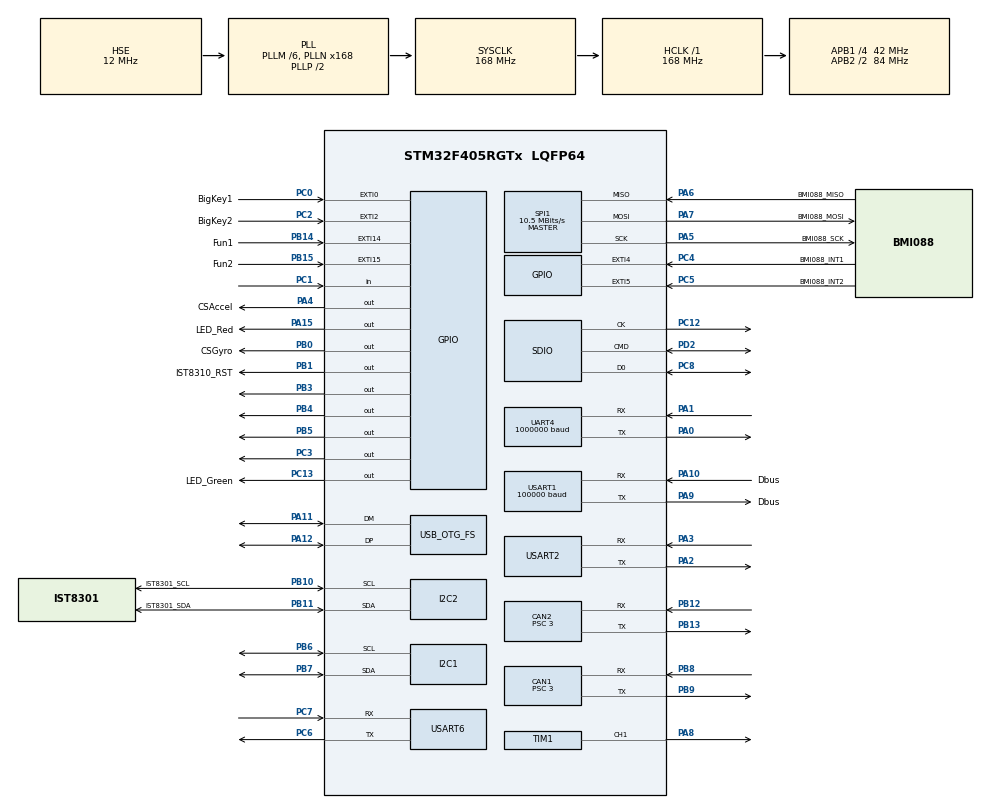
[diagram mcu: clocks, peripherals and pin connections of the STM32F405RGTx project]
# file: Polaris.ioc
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ADC1.Channel-0\#ChannelRegularConversion=ADC_CHANNEL_TEMPSENSOR
ADC1.Channel-1\#ChannelRegularConversion=ADC_CHANNEL_VREFINT
ADC1.Channel-2\#ChannelRegularConversion=ADC_CHANNEL_VBAT
ADC1.ContinuousConvMode=ENABLE
ADC1.DMAContinuousRequests=ENABLE
ADC1.EOCSelection=ADC_EOC_SEQ_CONV
ADC1.NbrOfConversion=3
ADC1.NbrOfConversionFlag=1
ADC1.Rank-0\#ChannelRegularConversion=1
ADC1.Rank-1\#ChannelRegularConversion=2
ADC1.Rank-2\#ChannelRegularConversion=3
ADC1.SamplingTime-0\#ChannelRegularConversion=ADC_SAMPLETIME_15CYCLES
ADC1.SamplingTime-1\#ChannelRegularConversion=ADC_SAMPLETIME_15CYCLES
ADC1.SamplingTime-2\#ChannelRegularConversion=ADC_SAMPLETIME_15CYCLES
ADC1.master=1
CAN1.BS1=CAN_BS1_9TQ
CAN1.BS2=CAN_BS2_4TQ
CAN1.CalculateBaudRate=1000000
CAN1.CalculateTimeBit=1000
CAN1.CalculateTimeQuantum=71.42857142857143
CAN1.Prescaler=3
CAN2.BS1=CAN_BS1_9TQ
CAN2.BS2=CAN_BS2_4TQ
CAN2.CalculateBaudRate=1000000
CAN2.CalculateTimeBit=1000
CAN2.CalculateTimeQuantum=71.42857142857143
CAN2.Prescaler=3
Dma.ADC1.7.Direction=DMA_PERIPH_TO_MEMORY
Dma.ADC1.7.FIFOMode=DMA_FIFOMODE_ENABLE
Dma.ADC1.7.FIFOThreshold=DMA_FIFO_THRESHOLD_FULL
Dma.ADC1.7.Instance=DMA2_Stream4
Dma.ADC1.7.MemBurst=DMA_MBURST_SINGLE
Dma.ADC1.7.MemDataAlignment=DMA_MDATAALIGN_WORD
Dma.ADC1.7.MemInc=DMA_MINC_ENABLE
Dma.ADC1.7.Mode=DMA_CIRCULAR
Dma.ADC1.7.PeriphBurst=DMA_PBURST_SINGLE
Dma.ADC1.7.PeriphDataAlignment=DMA_PDATAALIGN_WORD
Dma.ADC1.7.PeriphInc=DMA_PINC_DISABLE
Dma.ADC1.7.Priority=DMA_PRIORITY_LOW
Dma.I2C1_RX.6.Direction=DMA_PERIPH_TO_MEMORY
Dma.I2C1_RX.6.FIFOMode=DMA_FIFOMODE_DISABLE
Dma.I2C1_RX.6.Instance=DMA1_Stream0
Dma.I2C1_RX.6.MemDataAlignment=DMA_MDATAALIGN_BYTE
Dma.I2C1_RX.6.MemInc=DMA_MINC_ENABLE
Dma.I2C1_RX.6.Mode=DMA_CIRCULAR
Dma.I2C1_RX.6.PeriphDataAlignment=DMA_PDATAALIGN_BYTE
Dma.I2C1_RX.6.PeriphInc=DMA_PINC_DISABLE
Dma.I2C1_RX.6.Priority=DMA_PRIORITY_LOW
Dma.I2C1_TX.10.Direction=DMA_MEMORY_TO_PERIPH
Dma.I2C1_TX.10.FIFOMode=DMA_FIFOMODE_DISABLE
Dma.I2C1_TX.10.Instance=DMA1_Stream7
Dma.I2C1_TX.10.MemDataAlignment=DMA_MDATAALIGN_BYTE
Dma.I2C1_TX.10.MemInc=DMA_MINC_ENABLE
Dma.I2C1_TX.10.Mode=DMA_CIRCULAR
Dma.I2C1_TX.10.PeriphDataAlignment=DMA_PDATAALIGN_BYTE
Dma.I2C1_TX.10.PeriphInc=DMA_PINC_DISABLE
Dma.I2C1_TX.10.Priority=DMA_PRIORITY_VERY_HIGH
Dma.Request0=USART6_RX
Dma.Request1=USART2_RX
Dma.Request10=I2C1_TX
Dma.Request11=USART2_TX
Dma.Request12=UART4_TX
Dma.Request2=USART1_RX
Dma.Request3=UART4_RX
Dma.Request4=SPI1_RX
Dma.Request5=SPI1_TX
Dma.Request6=I2C1_RX
Dma.Request7=ADC1
Dma.Request8=SDIO_RX
Dma.Request9=SDIO_TX
Dma.SDIO_RX.8.Direction=DMA_PERIPH_TO_MEMORY
Dma.SDIO_RX.8.FIFOMode=DMA_FIFOMODE_ENABLE
Dma.SDIO_RX.8.FIFOThreshold=DMA_FIFO_THRESHOLD_FULL
Dma.SDIO_RX.8.Instance=DMA2_Stream6
Dma.SDIO_RX.8.MemBurst=DMA_MBURST_INC4
Dma.SDIO_RX.8.MemDataAlignment=DMA_MDATAALIGN_WORD
Dma.SDIO_RX.8.MemInc=DMA_MINC_ENABLE
Dma.SDIO_RX.8.Mode=DMA_PFCTRL
Dma.SDIO_RX.8.PeriphBurst=DMA_PBURST_INC4
Dma.SDIO_RX.8.PeriphDataAlignment=DMA_PDATAALIGN_WORD
Dma.SDIO_RX.8.PeriphInc=DMA_PINC_DISABLE
Dma.SDIO_RX.8.Priority=DMA_PRIORITY_LOW
Dma.SDIO_TX.9.Direction=DMA_MEMORY_TO_PERIPH
Dma.SDIO_TX.9.FIFOMode=DMA_FIFOMODE_ENABLE
Dma.SDIO_TX.9.FIFOThreshold=DMA_FIFO_THRESHOLD_FULL
Dma.SDIO_TX.9.Instance=DMA2_Stream3
Dma.SDIO_TX.9.MemBurst=DMA_MBURST_INC4
Dma.SDIO_TX.9.MemDataAlignment=DMA_MDATAALIGN_WORD
Dma.SDIO_TX.9.MemInc=DMA_MINC_ENABLE
Dma.SDIO_TX.9.Mode=DMA_PFCTRL
Dma.SDIO_TX.9.PeriphBurst=DMA_PBURST_INC4
Dma.SDIO_TX.9.PeriphDataAlignment=DMA_PDATAALIGN_WORD
Dma.SDIO_TX.9.PeriphInc=DMA_PINC_DISABLE
Dma.SDIO_TX.9.Priority=DMA_PRIORITY_LOW
Dma.SPI1_RX.4.Direction=DMA_PERIPH_TO_MEMORY
Dma.SPI1_RX.4.FIFOMode=DMA_FIFOMODE_DISABLE
Dma.SPI1_RX.4.Instance=DMA2_Stream0
Dma.SPI1_RX.4.MemDataAlignment=DMA_MDATAALIGN_BYTE
Dma.SPI1_RX.4.MemInc=DMA_MINC_ENABLE
Dma.SPI1_RX.4.Mode=DMA_CIRCULAR
Dma.SPI1_RX.4.PeriphDataAlignment=DMA_PDATAALIGN_BYTE
Dma.SPI1_RX.4.PeriphInc=DMA_PINC_DISABLE
Dma.SPI1_RX.4.Priority=DMA_PRIORITY_LOW
Dma.SPI1_TX.5.Direction=DMA_MEMORY_TO_PERIPH
Dma.SPI1_TX.5.FIFOMode=DMA_FIFOMODE_DISABLE
Dma.SPI1_TX.5.Instance=DMA2_Stream5
Dma.SPI1_TX.5.MemDataAlignment=DMA_MDATAALIGN_BYTE
Dma.SPI1_TX.5.MemInc=DMA_MINC_ENABLE
Dma.SPI1_TX.5.Mode=DMA_CIRCULAR
Dma.SPI1_TX.5.PeriphDataAlignment=DMA_PDATAALIGN_BYTE
Dma.SPI1_TX.5.PeriphInc=DMA_PINC_DISABLE
Dma.SPI1_TX.5.Priority=DMA_PRIORITY_LOW
Dma.UART4_RX.3.Direction=DMA_PERIPH_TO_MEMORY
Dma.UART4_RX.3.FIFOMode=DMA_FIFOMODE_DISABLE
Dma.UART4_RX.3.Instance=DMA1_Stream2
Dma.UART4_RX.3.MemDataAlignment=DMA_MDATAALIGN_BYTE
Dma.UART4_RX.3.MemInc=DMA_MINC_ENABLE
Dma.UART4_RX.3.Mode=DMA_CIRCULAR
Dma.UART4_RX.3.PeriphDataAlignment=DMA_PDATAALIGN_BYTE
Dma.UART4_RX.3.PeriphInc=DMA_PINC_DISABLE
Dma.UART4_RX.3.Priority=DMA_PRIORITY_LOW
Dma.UART4_TX.12.Direction=DMA_MEMORY_TO_PERIPH
Dma.UART4_TX.12.FIFOMode=DMA_FIFOMODE_DISABLE
Dma.UART4_TX.12.Instance=DMA1_Stream4
Dma.UART4_TX.12.MemDataAlignment=DMA_MDATAALIGN_BYTE
Dma.UART4_TX.12.MemInc=DMA_MINC_ENABLE
Dma.UART4_TX.12.Mode=DMA_NORMAL
Dma.UART4_TX.12.PeriphDataAlignment=DMA_PDATAALIGN_BYTE
Dma.UART4_TX.12.PeriphInc=DMA_PINC_DISABLE
Dma.UART4_TX.12.Priority=DMA_PRIORITY_LOW
Dma.USART1_RX.2.Direction=DMA_PERIPH_TO_MEMORY
Dma.USART1_RX.2.FIFOMode=DMA_FIFOMODE_DISABLE
Dma.USART1_RX.2.Instance=DMA2_Stream2
Dma.USART1_RX.2.MemDataAlignment=DMA_MDATAALIGN_BYTE
Dma.USART1_RX.2.MemInc=DMA_MINC_ENABLE
Dma.USART1_RX.2.Mode=DMA_CIRCULAR
Dma.USART1_RX.2.PeriphDataAlignment=DMA_PDATAALIGN_BYTE
Dma.USART1_RX.2.PeriphInc=DMA_PINC_DISABLE
Dma.USART1_RX.2.Priority=DMA_PRIORITY_LOW
Dma.USART2_RX.1.Direction=DMA_PERIPH_TO_MEMORY
Dma.USART2_RX.1.FIFOMode=DMA_FIFOMODE_DISABLE
Dma.USART2_RX.1.Instance=DMA1_Stream5
Dma.USART2_RX.1.MemDataAlignment=DMA_MDATAALIGN_BYTE
Dma.USART2_RX.1.MemInc=DMA_MINC_ENABLE
Dma.USART2_RX.1.Mode=DMA_CIRCULAR
Dma.USART2_RX.1.PeriphDataAlignment=DMA_PDATAALIGN_BYTE
Dma.USART2_RX.1.PeriphInc=DMA_PINC_DISABLE
Dma.USART2_RX.1.Priority=DMA_PRIORITY_LOW
Dma.USART2_TX.11.Direction=DMA_MEMORY_TO_PERIPH
Dma.USART2_TX.11.FIFOMode=DMA_FIFOMODE_DISABLE
Dma.USART2_TX.11.Instance=DMA1_Stream6
Dma.USART2_TX.11.MemDataAlignment=DMA_MDATAALIGN_BYTE
Dma.USART2_TX.11.MemInc=DMA_MINC_ENABLE
Dma.USART2_TX.11.Mode=DMA_NORMAL
Dma.USART2_TX.11.PeriphDataAlignment=DMA_PDATAALIGN_BYTE
Dma.USART2_TX.11.PeriphInc=DMA_PINC_DISABLE
Dma.USART2_TX.11.Priority=DMA_PRIORITY_LOW
Dma.USART6_RX.0.Direction=DMA_PERIPH_TO_MEMORY
Dma.USART6_RX.0.FIFOMode=DMA_FIFOMODE_DISABLE
Dma.USART6_RX.0.Instance=DMA2_Stream1
Dma.USART6_RX.0.MemDataAlignment=DMA_MDATAALIGN_BYTE
Dma.USART6_RX.0.MemInc=DMA_MINC_ENABLE
Dma.USART6_RX.0.Mode=DMA_CIRCULAR
Dma.USART6_RX.0.PeriphDataAlignment=DMA_PDATAALIGN_BYTE
Dma.USART6_RX.0.PeriphInc=DMA_PINC_DISABLE
Dma.USART6_RX.0.Priority=DMA_PRIORITY_LOW
FATFS.BSP.number=1
FATFS._CODE_PAGE=437
FATFS._FS_MINIMIZE=0
FATFS._USE_FIND=0
FATFS._USE_LFN=2
FATFS0.BSP.STBoard=false
FATFS0.BSP.api=Unknown
FATFS0.BSP.instance=PC1
FATFS0.BSP.ip=GPIO
FATFS0.BSP.mode=Input
FATFS0.BSP.name=Detect_SDIO
FATFS0.BSP.solution=PC1
FREERTOS.BinarySemaphores01=Shell_RxCMD,Dynamic,NULL
FREERTOS.INCLUDE_eTaskGetState=1
FREERTOS.INCLUDE_pcTaskGetTaskName=1
FREERTOS.INCLUDE_uxTaskGetStackHighWaterMark=1
FREERTOS.INCLUDE_uxTaskGetStackHighWaterMark2=1
FREERTOS.INCLUDE_vTaskCleanUpResources=1
FREERTOS.INCLUDE_vTaskDelayUntil=1
FREERTOS.INCLUDE_xQueueGetMutexHolder=1
FREERTOS.INCLUDE_xSemaphoreGetMutexHolder=1
FREERTOS.INCLUDE_xTaskAbortDelay=1
FREERTOS.INCLUDE_xTaskGetCurrentTaskHandle=1
FREERTOS.INCLUDE_xTaskGetHandle=1
FREERTOS.INCLUDE_xTimerPendFunctionCall=1
FREERTOS.Queues01=Key_Queue,16,uint16_t,0,Dynamic,NULL,NULL;Key_TriggerQueue,16,uint16_t,0,Dynamic,NULL,NULL
FREERTOS.Tasks01=Init_TASK,3,256,Init_Task,As weak,NULL,Dynamic,NULL,NULL;Ins_TASK,3,256,Ins_Task,As weak,NULL,Dynamic,NULL,NULL;Client_TASK,3,256,Client_Task,As weak,NULL,Dynamic,NULL,NULL;WatchDog_TASK,3,256,WatchDog_Task,As weak,NULL,Dynamic,NULL,NULL;Remote_TASK,3,256,Remote_Task,As weak,NULL,Dynamic,NULL,NULL;Comm_TASK,3,256,Comm_Task,As weak,NULL,Dynamic,NULL,NULL;Shell_TASK,2,256,Shell_Task,As weak,NULL,Dynamic,NULL,NULL;Quadruped_TASK,3,256,Quadruped_Task,As weak,NULL,Dynamic,NULL,NULL;WheelLeg_TASK,3,256,WheelLeg_Task,As weak,NULL,Dynamic,NULL,NULL;Gimbal_TASK,3,256,Gimbal_Task,As weak,NULL,Dynamic,NULL,NULL
FREERTOS.Timers01=Beeper_Timer,BeeperTimerCallback,osTimerPeriodic,As weak,NULL,Dynamic,NULL
FREERTOS.configCHECK_FOR_STACK_OVERFLOW=1
FREERTOS.configENABLE_FPU=1
FREERTOS.configGENERATE_RUN_TIME_STATS=1
FREERTOS.configIDLE_SHOULD_YIELD=1
FREERTOS.configMINIMAL_STACK_SIZE=256
FREERTOS.configRECORD_STACK_HIGH_ADDRESS=1
FREERTOS.configTIMER_TASK_PRIORITY=3
FREERTOS.configTIMER_TASK_STACK_DEPTH=256
FREERTOS.configUSE_APPLICATION_TASK_TAG=1
FREERTOS.configUSE_COUNTING_SEMAPHORES=0
FREERTOS.configUSE_DAEMON_TASK_STARTUP_HOOK=1
FREERTOS.configUSE_IDLE_HOOK=1
FREERTOS.configUSE_MALLOC_FAILED_HOOK=1
FREERTOS.configUSE_RECURSIVE_MUTEXES=0
FREERTOS.configUSE_STATS_FORMATTING_FUNCTIONS=1
FREERTOS.configUSE_TICK_HOOK=1
FREERTOS.configUSE_TIMERS=1
FREERTOS.configUSE_TRACE_FACILITY=1
I2C1.I2C_Mode=I2C_Fast
I2C2.I2C_Mode=I2C_Fast
Mcu.Family=STM32F4
Mcu.Name=STM32F405RGTx
Mcu.Package=LQFP64
NVIC.CAN1_RX0_IRQn=true\:5\:0\:true\:false\:true\:true\:true\:true\:true
NVIC.CAN1_RX1_IRQn=true\:5\:0\:false\:false\:true\:true\:true\:true\:true
NVIC.CAN2_RX0_IRQn=true\:5\:0\:false\:false\:true\:true\:true\:true\:true
NVIC.CAN2_RX1_IRQn=true\:5\:0\:false\:false\:true\:true\:true\:true\:true
NVIC.DMA1_Stream0_IRQn=true\:5\:0\:false\:false\:true\:true\:false\:true\:true
NVIC.DMA1_Stream2_IRQn=true\:5\:0\:false\:false\:true\:true\:false\:true\:true
NVIC.DMA1_Stream4_IRQn=true\:5\:0\:false\:false\:true\:true\:false\:true\:true
NVIC.DMA1_Stream5_IRQn=true\:5\:0\:false\:false\:true\:true\:false\:true\:true
NVIC.DMA1_Stream6_IRQn=true\:5\:0\:false\:false\:true\:true\:false\:true\:true
NVIC.DMA1_Stream7_IRQn=true\:5\:0\:false\:false\:true\:false\:false\:true\:true
NVIC.DMA2_Stream0_IRQn=true\:5\:0\:false\:false\:true\:true\:false\:true\:true
NVIC.DMA2_Stream1_IRQn=true\:5\:0\:false\:false\:true\:true\:false\:true\:true
NVIC.DMA2_Stream2_IRQn=true\:5\:0\:false\:false\:true\:true\:false\:true\:true
NVIC.DMA2_Stream3_IRQn=true\:5\:0\:false\:false\:true\:true\:false\:true\:true
NVIC.DMA2_Stream4_IRQn=true\:5\:0\:false\:false\:true\:true\:false\:true\:true
NVIC.DMA2_Stream5_IRQn=true\:5\:0\:false\:false\:true\:true\:false\:true\:true
NVIC.DMA2_Stream6_IRQn=true\:5\:0\:false\:false\:true\:true\:false\:true\:true
NVIC.EXTI0_IRQn=true\:5\:0\:false\:false\:true\:true\:true\:true\:true
NVIC.EXTI15_10_IRQn=true\:5\:0\:false\:false\:true\:true\:true\:true\:true
NVIC.EXTI2_IRQn=true\:5\:0\:false\:false\:true\:true\:true\:true\:true
NVIC.EXTI4_IRQn=true\:5\:0\:false\:false\:true\:true\:true\:true\:true
NVIC.EXTI9_5_IRQn=true\:5\:0\:false\:false\:true\:true\:true\:true\:true
NVIC.OTG_FS_IRQn=true\:5\:0\:false\:false\:true\:true\:true\:true\:true
NVIC.PriorityGroup=NVIC_PRIORITYGROUP_4
NVIC.SDIO_IRQn=true\:5\:0\:true\:false\:true\:true\:true\:true\:true
NVIC.SPI1_IRQn=true\:5\:0\:false\:false\:true\:true\:true\:true\:true
NVIC.TIM2_IRQn=true\:5\:0\:true\:false\:true\:true\:true\:true\:true
NVIC.TIM6_DAC_IRQn=true\:4\:0\:true\:false\:true\:false\:false\:true\:true
NVIC.TimeBase=TIM6_DAC_IRQn
NVIC.TimeBaseIP=TIM6
NVIC.UART4_IRQn=true\:5\:0\:false\:false\:true\:true\:true\:true\:true
NVIC.USART1_IRQn=true\:5\:0\:false\:false\:true\:true\:true\:true\:true
NVIC.USART2_IRQn=true\:5\:0\:false\:false\:true\:true\:true\:true\:true
NVIC.USART6_IRQn=true\:5\:0\:false\:false\:true\:true\:true\:true\:true
PA0-WKUP.Mode=Asynchronous
PA0-WKUP.Signal=UART4_TX
PA1.Mode=Asynchronous
PA1.Signal=UART4_RX
PA10.GPIO_Label=Dbus
PA10.Mode=Asynchronous
PA10.Signal=USART1_RX
PA11.Mode=Device_Only
PA11.Signal=USB_OTG_FS_DM
PA12.GPIO_PuPd=GPIO_NOPULL
PA12.Mode=Device_Only
PA12.Signal=USB_OTG_FS_DP
PA13.Mode=Serial_Wire
PA13.Signal=SYS_JTMS-SWDIO
PA14.Mode=Serial_Wire
PA14.Signal=SYS_JTCK-SWCLK
PA15.GPIO_Label=LED_Red
PA15.Signal=GPIO_Output
PA2.Mode=Asynchronous
PA2.Signal=USART2_TX
PA3.Mode=Asynchronous
PA3.Signal=USART2_RX
PA4.GPIO_Label=CSAccel
PA4.PinState=GPIO_PIN_SET
PA4.Signal=GPIO_Output
PA5.GPIO_Label=BMI088_SCK
PA5.Mode=Full_Duplex_Master
PA5.Signal=SPI1_SCK
PA6.GPIO_Label=BMI088_MISO
PA6.Mode=Full_Duplex_Master
PA6.Signal=SPI1_MISO
PA7.GPIO_Label=BMI088_MOSI
PA7.Mode=Full_Duplex_Master
PA7.Signal=SPI1_MOSI
PA8.Signal=S_TIM1_CH1
PA9.GPIO_Label=Dbus
PA9.Mode=Asynchronous
PA9.Signal=USART1_TX
PB0.GPIO_Label=CSGyro
PB0.PinState=GPIO_PIN_SET
PB0.Signal=GPIO_Output
PB1.GPIO_Label=IST8310_RST
PB1.Signal=GPIO_Output
PB10.GPIO_Label=IST8301_SCL
PB10.Mode=I2C
PB10.Signal=I2C2_SCL
PB11.GPIO_Label=IST8301_SDA
PB11.Mode=I2C
PB11.Signal=I2C2_SDA
PB12.Mode=CAN_Activate
PB12.Signal=CAN2_RX
PB13.Mode=CAN_Activate
PB13.Signal=CAN2_TX
PB14.GPIO_Label=Fun1
PB14.GPIO_ModeDefaultEXTI=GPIO_MODE_IT_RISING_FALLING
PB14.Signal=GPXTI14
PB15.GPIO_Label=Fun2
PB15.GPIO_ModeDefaultEXTI=GPIO_MODE_IT_RISING_FALLING
PB15.Signal=GPXTI15
PB3.Signal=GPIO_Output
PB4.Signal=GPIO_Output
PB5.Signal=GPIO_Output
PB6.Mode=I2C
PB6.Signal=I2C1_SCL
PB7.Mode=I2C
PB7.Signal=I2C1_SDA
PB8.Mode=CAN_Activate
PB8.Signal=CAN1_RX
PB9.Mode=CAN_Activate
PB9.Signal=CAN1_TX
PC0.GPIO_Label=BigKey1
PC0.GPIO_ModeDefaultEXTI=GPIO_MODE_IT_RISING_FALLING
PC0.Signal=GPXTI0
PC1.Signal=GPIO_Input
PC12.Mode=SD_1_bit
PC12.Signal=SDIO_CK
PC13-ANTI_TAMP.GPIO_Label=LED_Green
PC13-ANTI_TAMP.Signal=GPIO_Output
PC14-OSC32_IN.Mode=LSE-External-Oscillator
PC14-OSC32_IN.Signal=RCC_OSC32_IN
PC15-OSC32_OUT.Mode=LSE-External-Oscillator
PC15-OSC32_OUT.Signal=RCC_OSC32_OUT
PC2.GPIO_Label=BigKey2
PC2.GPIO_ModeDefaultEXTI=GPIO_MODE_IT_RISING_FALLING
PC2.Signal=GPXTI2
PC3.Signal=GPIO_Output
PC4.GPIO_Label=BMI088_INT1
PC4.Signal=GPXTI4
PC5.GPIO_Label=BMI088_INT2
PC5.Signal=GPXTI5
PC6.Mode=Asynchronous
PC6.Signal=USART6_TX
PC7.Mode=Asynchronous
PC7.Signal=USART6_RX
PC8.GPIO_PuPd=GPIO_NOPULL
PC8.Mode=SD_1_bit
PC8.Signal=SDIO_D0
PD2.GPIO_PuPd=GPIO_NOPULL
PD2.Mode=SD_1_bit
PD2.Signal=SDIO_CMD
PH0-OSC_IN.Mode=HSE-External-Oscillator
PH0-OSC_IN.Signal=RCC_OSC_IN
PH1-OSC_OUT.Mode=HSE-External-Oscillator
PH1-OSC_OUT.Signal=RCC_OSC_OUT
ProjectManager.HeapSize=0x4000
ProjectManager.StackSize=0x4000
ProjectManager.TargetToolchain=MDK-ARM V5.32
RCC.48MHZClocksFreq_Value=48000000
RCC.AHBFreq_Value=168000000
RCC.APB1CLKDivider=RCC_HCLK_DIV4
RCC.APB1Freq_Value=42000000
RCC.APB1TimFreq_Value=84000000
RCC.APB2CLKDivider=RCC_HCLK_DIV2
RCC.APB2Freq_Value=84000000
RCC.APB2TimFreq_Value=168000000
RCC.CortexFreq_Value=168000000
RCC.HCLKFreq_Value=168000000
RCC.HSE_VALUE=12000000
RCC.HSI_VALUE=16000000
RCC.PLLM=6
RCC.PLLN=168
RCC.PLLQ=7
RCC.RCC_RTC_Clock_Source=RCC_RTCCLKSOURCE_LSE
RCC.RCC_RTC_Clock_SourceVirtual=RCC_RTCCLKSOURCE_LSE
RCC.SYSCLKFreq_VALUE=168000000
RCC.SYSCLKSource=RCC_SYSCLKSOURCE_PLLCLK
RCC.VCOOutputFreq_Value=336000000
SDIO.ClockDiv=22
SDIO.HardwareFlowControl=SDIO_HARDWARE_FLOW_CONTROL_DISABLE
SH.S_TIM1_CH1.0=TIM1_CH1,PWM Generation1 CH1
SPI1.BaudRatePrescaler=SPI_BAUDRATEPRESCALER_8
SPI1.CLKPhase=SPI_PHASE_2EDGE
SPI1.CLKPolarity=SPI_POLARITY_HIGH
SPI1.CalculateBaudRate=10.5 MBits/s
SPI1.Direction=SPI_DIRECTION_2LINES
SPI1.Mode=SPI_MODE_MASTER
SPI1.VirtualType=VM_MASTER
TIM1.Channel-PWM\ Generation1\ CH1=TIM_CHANNEL_1
TIM2.Period=19
TIM2.Prescaler=83
UART4.BaudRate=1000000
UART4.VirtualMode=Asynchronous
USART1.BaudRate=100000
USART1.Parity=PARITY_EVEN
USART1.VirtualMode=VM_ASYNC
USART2.VirtualMode=VM_ASYNC
USART6.VirtualMode=VM_ASYNC
USB_DEVICE.APP_RX_DATA_SIZE-CDC_FS=2048
USB_DEVICE.APP_TX_DATA_SIZE-CDC_FS=2048
USB_DEVICE.CLASS_NAME_FS=CDC
USB_DEVICE.MANUFACTURER_STRING-CDC_FS=STMicroelectronicsPolar
USB_DEVICE.VirtualMode-CDC_FS=Cdc
USB_DEVICE.VirtualModeFS=Cdc_FS
USB_OTG_FS.Sof_enable=DISABLE
USB_OTG_FS.VirtualMode=Device_Only
VP_ADC1_TempSens_Input.Mode=IN-TempSens
VP_ADC1_Vbat_Input.Mode=IN-Vbat
VP_ADC1_Vref_Input.Mode=IN-Vrefint
VP_CRC_VS_CRC.Mode=CRC_Activate
VP_FATFS_VS_SDIO.Mode=SDIO
VP_FREERTOS_VS_CMSIS_V1.Mode=CMSIS_V1
VP_RNG_VS_RNG.Mode=RNG_Activate
VP_RTC_VS_RTC_Activate.Mode=RTC_Enabled
VP_RTC_VS_RTC_Calendar.Mode=RTC_Calendar
VP_SYS_VS_tim6.Mode=TIM6
VP_TIM2_VS_ClockSourceINT.Mode=Internal
VP_TIM8_VS_ClockSourceINT.Mode=Internal
VP_USB_DEVICE_VS_USB_DEVICE_CDC_FS.Mode=CDC_FS
board=custom

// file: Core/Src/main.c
/* USER CODE BEGIN Header */
/**
  ******************************************************************************
  * @file           : main.c
  * @brief          : Main program body
  ******************************************************************************
  * @attention
  *
  * Copyright (c) 2023 STMicroelectronics.
  * All rights reserved.
  *
  * This software is licensed under terms that can be found in the LICENSE file
  * in the root directory of this software component.
  * If no LICENSE file comes with this software, it is provided AS-IS.
  *
  ******************************************************************************
  */
/* USER CODE END Header */
#include "main.h"
#include "cmsis_os.h"
#include "adc.h"
#include "can.h"
#include "crc.h"
#include "dma.h"
#include "fatfs.h"
#include "i2c.h"
#include "rng.h"
#include "rtc.h"
#include "sdio.h"
#include "spi.h"
#include "tim.h"
#include "usart.h"
#include "usb_device.h"
#include "gpio.h"

/* USER CODE BEGIN Includes */
#include "app_init.h"
/* USER CODE END Includes */

void SystemClock_Config(void);
void MX_FREERTOS_Init(void);

/* USER CODE BEGIN 0 */
Main_FuncTypeEnum Main_Type;
/* USER CODE END 0 */

int main(void)
{

  /* MCU Configuration--------------------------------------------------------*/

  /* Reset of all peripherals, Initializes the Flash interface and the Systick. */
  HAL_Init();

  /* Configure the system clock */
  SystemClock_Config();

  /* Initialize all configured peripherals */
  MX_GPIO_Init();
  MX_DMA_Init();
  MX_CAN1_Init();
  MX_CAN2_Init();
  MX_CRC_Init();
  MX_I2C1_Init();
  MX_I2C2_Init();
  MX_RNG_Init();
  MX_RTC_Init();
  MX_SDIO_SD_Init();
  MX_SPI1_Init();
  MX_UART4_Init();
  MX_USART1_UART_Init();
  MX_USART2_UART_Init();
  MX_USART6_UART_Init();
  MX_ADC1_Init();
  MX_FATFS_Init();
  MX_TIM8_Init();
  MX_TIM1_Init();
  MX_TIM2_Init();
  /* USER CODE BEGIN 2 */
	Init_InitAll();
  /* USER CODE END 2 */

  /* Call init function for freertos objects (in freertos.c) */
  MX_FREERTOS_Init();

  /* Start scheduler */
  osKernelStart();
  /* We should never get here as control is now taken by the scheduler */
  /* Infinite loop */
  while (1)
  {

  }
}

void SystemClock_Config(void)
{
  RCC_OscInitTypeDef RCC_OscInitStruct = {0};
  RCC_ClkInitTypeDef RCC_ClkInitStruct = {0};

  /** Configure the main internal regulator output voltage
  */
  __HAL_RCC_PWR_CLK_ENABLE();
  __HAL_PWR_VOLTAGESCALING_CONFIG(PWR_REGULATOR_VOLTAGE_SCALE1);

  /** Initializes the RCC Oscillators according to the specified parameters
  * in the RCC_OscInitTypeDef structure.
  */
  RCC_OscInitStruct.OscillatorType = RCC_OSCILLATORTYPE_HSE|RCC_OSCILLATORTYPE_LSE;
  RCC_OscInitStruct.HSEState = RCC_HSE_ON;
  RCC_OscInitStruct.LSEState = RCC_LSE_ON;
  RCC_OscInitStruct.PLL.PLLState = RCC_PLL_ON;
  RCC_OscInitStruct.PLL.PLLSource = RCC_PLLSOURCE_HSE;
  RCC_OscInitStruct.PLL.PLLM = 6;
  RCC_OscInitStruct.PLL.PLLN = 168;
  RCC_OscInitStruct.PLL.PLLP = RCC_PLLP_DIV2;
  RCC_OscInitStruct.PLL.PLLQ = 7;
  if (HAL_RCC_OscConfig(&RCC_OscInitStruct) != HAL_OK)
  {
    Error_Handler();
  }

  /** Initializes the CPU, AHB and APB buses clocks
  */
  RCC_ClkInitStruct.ClockType = RCC_CLOCKTYPE_HCLK|RCC_CLOCKTYPE_SYSCLK
                              |RCC_CLOCKTYPE_PCLK1|RCC_CLOCKTYPE_PCLK2;
  RCC_ClkInitStruct.SYSCLKSource = RCC_SYSCLKSOURCE_PLLCLK;
  RCC_ClkInitStruct.AHBCLKDivider = RCC_SYSCLK_DIV1;
  RCC_ClkInitStruct.APB1CLKDivider = RCC_HCLK_DIV4;
  RCC_ClkInitStruct.APB2CLKDivider = RCC_HCLK_DIV2;

  if (HAL_RCC_ClockConfig(&RCC_ClkInitStruct, FLASH_LATENCY_5) != HAL_OK)
  {
    Error_Handler();
  }
}

/* USER CODE BEGIN 4 */
#include "sys_dwt.h"
/* USER CODE END 4 */

void HAL_TIM_PeriodElapsedCallback(TIM_HandleTypeDef *htim)
{
  if (htim->Instance == TIM6) {
    HAL_IncTick();
  }
  /* USER CODE BEGIN Callback 1 */
  if (htim->Instance == TIM6) {
    DWT_SysTimeUpdate();
  }
  /* USER CODE END Callback 1 */
}

void Error_Handler(void)
{
  /* USER CODE BEGIN Error_Handler_Debug */
  /* User can add his own implementation to report the HAL error return state */
  __disable_irq();
  while (1)
  {
	  NVIC_SystemReset();
  }
  /* USER CODE END Error_Handler_Debug */
}

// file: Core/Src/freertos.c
/* USER CODE BEGIN Header */
/**
  ******************************************************************************
  * File Name          : freertos.c
  * Description        : Code for freertos applications
  ******************************************************************************
  * @attention
  *
  * Copyright (c) 2023 STMicroelectronics.
  * All rights reserved.
  *
  * This software is licensed under terms that can be found in the LICENSE file
  * in the root directory of this software component.
  * If no LICENSE file comes with this software, it is provided AS-IS.
  *
  ******************************************************************************
  */
/* USER CODE END Header */

#include "FreeRTOS.h"
#include "task.h"
#include "main.h"
#include "cmsis_os.h"

/* USER CODE BEGIN PD */
#include "sys_dwt.h"

/* USER CODE END PD */

osThreadId Init_TASKHandle;
osThreadId Ins_TASKHandle;
osThreadId Client_TASKHandle;
osThreadId WatchDog_TASKHandle;
osThreadId Remote_TASKHandle;
osThreadId Comm_TASKHandle;
osThreadId Shell_TASKHandle;
osThreadId Quadruped_TASKHandle;
osThreadId WheelLeg_TASKHandle;
osThreadId Gimbal_TASKHandle;
osMessageQId Key_QueueHandle;
osMessageQId Key_TriggerQueueHandle;
osTimerId Beeper_TimerHandle;
osSemaphoreId Shell_RxCMDHandle;

void Init_Task(void const * argument);
void Ins_Task(void const * argument);
void Client_Task(void const * argument);
void WatchDog_Task(void const * argument);
void Remote_Task(void const * argument);
void Comm_Task(void const * argument);
void Shell_Task(void const * argument);
void Quadruped_Task(void const * argument);
void WheelLeg_Task(void const * argument);
void Gimbal_Task(void const * argument);
void BeeperTimerCallback(void const * argument);

extern void MX_USB_DEVICE_Init(void);
void MX_FREERTOS_Init(void); /* (MISRA C 2004 rule 8.1) */

/* GetIdleTaskMemory prototype (linked to static allocation support) */
void vApplicationGetIdleTaskMemory( StaticTask_t **ppxIdleTaskTCBBuffer, StackType_t **ppxIdleTaskStackBuffer, uint32_t *pulIdleTaskStackSize );

/* GetTimerTaskMemory prototype (linked to static allocation support) */
void vApplicationGetTimerTaskMemory( StaticTask_t **ppxTimerTaskTCBBuffer, StackType_t **ppxTimerTaskStackBuffer, uint32_t *pulTimerTaskStackSize );

/* Hook prototypes */
void configureTimerForRunTimeStats(void);
unsigned long getRunTimeCounterValue(void);
void vApplicationIdleHook(void);
void vApplicationTickHook(void);
void vApplicationStackOverflowHook(xTaskHandle xTask, signed char *pcTaskName);
void vApplicationMallocFailedHook(void);
void vApplicationDaemonTaskStartupHook(void);

/* USER CODE BEGIN 1 */
/* Functions needed when configGENERATE_RUN_TIME_STATS is on */
__weak void configureTimerForRunTimeStats(void)
{

}

__weak unsigned long getRunTimeCounterValue(void)
{
    return DWT_GetTimeline_us();
	//return 0;
}
/* USER CODE END 1 */

/* USER CODE BEGIN 2 */
__weak void vApplicationIdleHook( void )
{
   /* vApplicationIdleHook() will only be called if configUSE_IDLE_HOOK is set
   to 1 in FreeRTOSConfig.h. It will be called on each iteration of the idle
   task. It is essential that code added to this hook function never attempts
   to block in any way (for example, call xQueueReceive() with a block time
   specified, or call vTaskDelay()). If the application makes use of the
   vTaskDelete() API function (as this demo application does) then it is also
   important that vApplicationIdleHook() is permitted to return to its calling
   function, because it is the responsibility of the idle task to clean up
   memory allocated by the kernel to any task that has since been deleted. */
}
/* USER CODE END 2 */

/* USER CODE BEGIN 3 */
__weak void vApplicationTickHook( void )
{
   /* This function will be called by each tick interrupt if
   configUSE_TICK_HOOK is set to 1 in FreeRTOSConfig.h. User code can be
   added here, but the tick hook is called from an interrupt context, so
   code must not attempt to block, and only the interrupt safe FreeRTOS API
   functions can be used (those that end in FromISR()). */
}
/* USER CODE END 3 */

/* USER CODE BEGIN 4 */
__weak void vApplicationStackOverflowHook(xTaskHandle xTask, signed char *pcTaskName)
{
   /* Run time stack overflow checking is performed if
   configCHECK_FOR_STACK_OVERFLOW is defined to 1 or 2. This hook function is
   called if a stack overflow is detected. */
}
/* USER CODE END 4 */

/* USER CODE BEGIN 5 */
__weak void vApplicationMallocFailedHook(void)
{
   /* vApplicationMallocFailedHook() will only be called if
   configUSE_MALLOC_FAILED_HOOK is set to 1 in FreeRTOSConfig.h. It is a hook
   function that will get called if a call to pvPortMalloc() fails.
   pvPortMalloc() is called internally by the kernel whenever a task, queue,
   timer or semaphore is created. It is also called by various parts of the
   demo application. If heap_1.c or heap_2.c are used, then the size of the
   heap available to pvPortMalloc() is defined by configTOTAL_HEAP_SIZE in
   FreeRTOSConfig.h, and the xPortGetFreeHeapSize() API function can be used
   to query the size of free heap space that remains (although it does not
   provide information on how the remaining heap might be fragmented). */
}
/* USER CODE END 5 */

/* USER CODE BEGIN DAEMON_TASK_STARTUP_HOOK */
void vApplicationDaemonTaskStartupHook(void)
{
}
/* USER CODE END DAEMON_TASK_STARTUP_HOOK */

/* USER CODE BEGIN GET_IDLE_TASK_MEMORY */
static StaticTask_t xIdleTaskTCBBuffer;
static StackType_t xIdleStack[configMINIMAL_STACK_SIZE];

void vApplicationGetIdleTaskMemory( StaticTask_t **ppxIdleTaskTCBBuffer, StackType_t **ppxIdleTaskStackBuffer, uint32_t *pulIdleTaskStackSize )
{
  *ppxIdleTaskTCBBuffer = &xIdleTaskTCBBuffer;
  *ppxIdleTaskStackBuffer = &xIdleStack[0];
  *pulIdleTaskStackSize = configMINIMAL_STACK_SIZE;
  /* place for user code */
}
/* USER CODE END GET_IDLE_TASK_MEMORY */

/* USER CODE BEGIN GET_TIMER_TASK_MEMORY */
static StaticTask_t xTimerTaskTCBBuffer;
static StackType_t xTimerStack[configTIMER_TASK_STACK_DEPTH];

void vApplicationGetTimerTaskMemory( StaticTask_t **ppxTimerTaskTCBBuffer, StackType_t **ppxTimerTaskStackBuffer, uint32_t *pulTimerTaskStackSize )
{
  *ppxTimerTaskTCBBuffer = &xTimerTaskTCBBuffer;
  *ppxTimerTaskStackBuffer = &xTimerStack[0];
  *pulTimerTaskStackSize = configTIMER_TASK_STACK_DEPTH;
  /* place for user code */
}
/* USER CODE END GET_TIMER_TASK_MEMORY */

void MX_FREERTOS_Init(void) {

  /* Create the semaphores(s) */
  /* definition and creation of Shell_RxCMD */
  osSemaphoreDef(Shell_RxCMD);
  Shell_RxCMDHandle = osSemaphoreCreate(osSemaphore(Shell_RxCMD), 1);

  /* Create the timer(s) */
  /* definition and creation of Beeper_Timer */
  osTimerDef(Beeper_Timer, BeeperTimerCallback);
  Beeper_TimerHandle = osTimerCreate(osTimer(Beeper_Timer), osTimerPeriodic, NULL);

  /* Create the queue(s) */
  /* definition and creation of Key_Queue */
  osMessageQDef(Key_Queue, 16, uint16_t);
  Key_QueueHandle = osMessageCreate(osMessageQ(Key_Queue), NULL);

  /* definition and creation of Key_TriggerQueue */
  osMessageQDef(Key_TriggerQueue, 16, uint16_t);
  Key_TriggerQueueHandle = osMessageCreate(osMessageQ(Key_TriggerQueue), NULL);

  /* Create the thread(s) */
  /* definition and creation of Init_TASK */
  osThreadDef(Init_TASK, Init_Task, osPriorityRealtime, 0, 256);
  Init_TASKHandle = osThreadCreate(osThread(Init_TASK), NULL);

  /* definition and creation of Ins_TASK */
  osThreadDef(Ins_TASK, Ins_Task, osPriorityRealtime, 0, 256);
  Ins_TASKHandle = osThreadCreate(osThread(Ins_TASK), NULL);

  /* definition and creation of Client_TASK */
  osThreadDef(Client_TASK, Client_Task, osPriorityRealtime, 0, 256);
  Client_TASKHandle = osThreadCreate(osThread(Client_TASK), NULL);

  /* definition and creation of WatchDog_TASK */
  osThreadDef(WatchDog_TASK, WatchDog_Task, osPriorityRealtime, 0, 256);
  WatchDog_TASKHandle = osThreadCreate(osThread(WatchDog_TASK), NULL);

  /* definition and creation of Remote_TASK */
  osThreadDef(Remote_TASK, Remote_Task, osPriorityRealtime, 0, 256);
  Remote_TASKHandle = osThreadCreate(osThread(Remote_TASK), NULL);

  /* definition and creation of Comm_TASK */
  osThreadDef(Comm_TASK, Comm_Task, osPriorityRealtime, 0, 256);
  Comm_TASKHandle = osThreadCreate(osThread(Comm_TASK), NULL);

  /* definition and creation of Shell_TASK */
  osThreadDef(Shell_TASK, Shell_Task, osPriorityHigh, 0, 256);
  Shell_TASKHandle = osThreadCreate(osThread(Shell_TASK), NULL);

  /* definition and creation of Quadruped_TASK */
  osThreadDef(Quadruped_TASK, Quadruped_Task, osPriorityRealtime, 0, 256);
  Quadruped_TASKHandle = osThreadCreate(osThread(Quadruped_TASK), NULL);

  /* definition and creation of WheelLeg_TASK */
  osThreadDef(WheelLeg_TASK, WheelLeg_Task, osPriorityRealtime, 0, 256);
  WheelLeg_TASKHandle = osThreadCreate(osThread(WheelLeg_TASK), NULL);

  /* definition and creation of Gimbal_TASK */
  osThreadDef(Gimbal_TASK, Gimbal_Task, osPriorityRealtime, 0, 256);
  Gimbal_TASKHandle = osThreadCreate(osThread(Gimbal_TASK), NULL);

}

__weak void Init_Task(void const * argument)
{
  /* init code for USB_DEVICE */
  MX_USB_DEVICE_Init();
  for(;;)
  {
    osDelay(1);
  }
}

__weak void Ins_Task(void const * argument)
{
  for(;;)
  {
    osDelay(1);
  }
}

__weak void Client_Task(void const * argument)
{
  for(;;)
  {
    osDelay(1);
  }
}

__weak void WatchDog_Task(void const * argument)
{
  for(;;)
  {
    osDelay(1);
  }
}

__weak void Remote_Task(void const * argument)
{
  for(;;)
  {
    osDelay(1);
  }
}

__weak void Comm_Task(void const * argument)
{
  for(;;)
  {
    osDelay(1);
  }
}

__weak void Shell_Task(void const * argument)
{
  for(;;)
  {
    osDelay(1);
  }
}

__weak void Quadruped_Task(void const * argument)
{
  for(;;)
  {
    osDelay(1);
  }
}

__weak void WheelLeg_Task(void const * argument)
{
  for(;;)
  {
    osDelay(1);
  }
}

__weak void Gimbal_Task(void const * argument)
{
  for(;;)
  {
    osDelay(1);
  }
}

/* BeeperTimerCallback function */
__weak void BeeperTimerCallback(void const * argument)
{
}
